# iqn_iqs register map
Vendor: Texas Instruments
Peripheral module from a debugger description file (folder Keystone2).
Registers are 32-bit, read-write, no defined reset value unless marked. A register's access mark holds for its fields unless they carry their own. Offsets are as the file gives them; lines under a group give offsets from that group; [hi:lo] are bit positions; {n}, {i} and the like mark numbered series; 'fields as' and 'values as' point back to an identical list; <NAME> marks a mode.

## IQN_IQS
0x00 IQS_Ingress_PKTDMA_Configuration_Register — (1 of 1, stride 0)
  [0] pb_sel — Sets level where the PKTDMA FIFO pushback occurs on ingress ports that can be pushed back on.
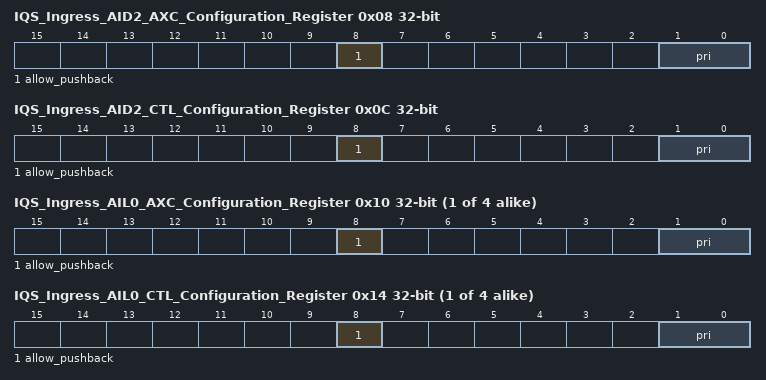
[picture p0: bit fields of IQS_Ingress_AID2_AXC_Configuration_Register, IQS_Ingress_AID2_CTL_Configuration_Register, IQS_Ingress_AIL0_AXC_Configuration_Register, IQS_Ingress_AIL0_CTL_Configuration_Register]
0x08 IQS_Ingress_AID2_AXC_Configuration_Register — (1 of 1, stride 0)
  [8] allow_pushback — When set allows the IQS to push back on the ingress PSI bus of this port due to the PKTDMA FIFO being too full. This allows reserving atleast 1/2 or 1/4 of the PKTDMA FIFO for the non-pushback ports.
  [1:0] pri — Sets ingress port arbitration priority. Typically higher speed standards require higher priorities and control ports can use lower priorities. A 0 is highest priority.
0x0C IQS_Ingress_AID2_CTL_Configuration_Register — (1 of 1, stride 0)
  fields as IQS_Ingress_AID2_AXC_Configuration_Register
{0x10+8i} IQS_Ingress_AIL{i}_AXC_Configuration_Register (i=0..3) — (1 of 1, stride 0)
  fields as IQS_Ingress_AID2_AXC_Configuration_Register
{0x14+8i} IQS_Ingress_AIL{i}_CTL_Configuration_Register (i=0..3) — (1 of 1, stride 0)
  fields as IQS_Ingress_AID2_AXC_Configuration_Register
0x200 IQS_Ingress_DIO2_PSI_Configuration_Register — (1 of 1, stride 0)
  [1:0] pri — Sets ingress DIO2 PSI channel priority. Typically higher speed standards require higher priorities and control ports can use lower priorities. A 0 is highest priority.
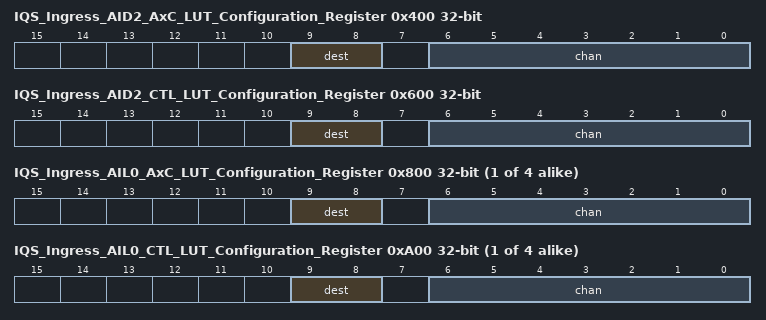
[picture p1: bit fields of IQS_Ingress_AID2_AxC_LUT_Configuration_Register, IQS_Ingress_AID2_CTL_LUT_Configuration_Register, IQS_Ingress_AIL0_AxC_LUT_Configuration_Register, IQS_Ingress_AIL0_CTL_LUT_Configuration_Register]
0x400 IQS_Ingress_AID2_AxC_LUT_Configuration_Register — (1 of 1, stride 0)
  [9:8] dest — Selects destination port.
  [6:0] chan — Channel to use in the destination port.
0x600 IQS_Ingress_AID2_CTL_LUT_Configuration_Register — (1 of 1, stride 0)
  fields as IQS_Ingress_AID2_AxC_LUT_Configuration_Register
{0x800+0x400*i} IQS_Ingress_AIL{i}_AxC_LUT_Configuration_Register (i=0..3) — (1 of 1, stride 0)
  fields as IQS_Ingress_AID2_AxC_LUT_Configuration_Register
{0xA00+0x400*i} IQS_Ingress_AIL{i}_CTL_LUT_Configuration_Register (i=0..3) — (1 of 1, stride 0)
  fields as IQS_Ingress_AID2_AxC_LUT_Configuration_Register
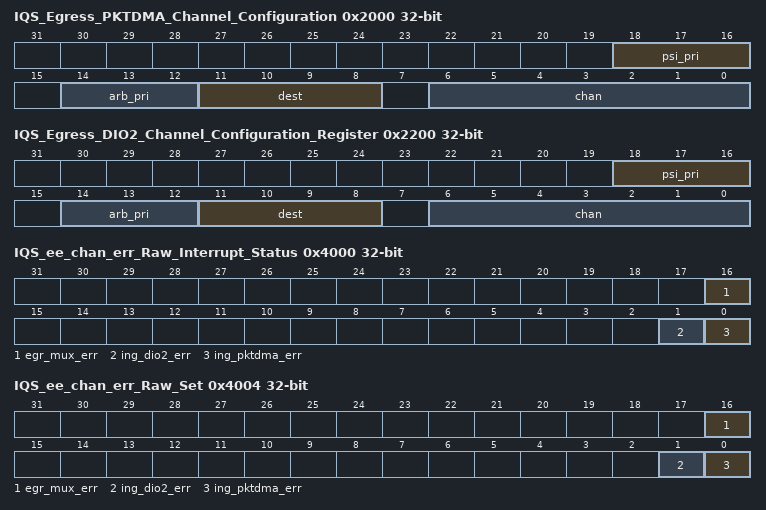
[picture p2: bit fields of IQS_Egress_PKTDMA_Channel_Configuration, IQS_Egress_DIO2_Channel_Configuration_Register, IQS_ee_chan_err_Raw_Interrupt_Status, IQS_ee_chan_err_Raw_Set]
0x2000 IQS_Egress_PKTDMA_Channel_Configuration — (1 of 1, stride 0)
  [18:16] psi_pri — PSI priority from the IQS output FIFOs to the destination module. Typically set the same as the arb_pri setting. A 0 is highest priority.
  [14:12] arb_pri — Arbitration priority of each channel for transfers between the PKTDMA and the output FIFOs. Typically higher speed standards require higher priorities and control ports can use lower priorities. A 0 is highest priority.
  [11:8] dest — Selects destination port.
  [6:0] chan — Channel to use in the destination port.
0x2200 IQS_Egress_DIO2_Channel_Configuration_Register — (1 of 1, stride 0)
  [18:16] psi_pri — PSI priority from the IQS output FIFOs to the destination module. Typically set the same as the arb_pri setting.A 0 is highest priority.
  [14:12] arb_pri — Arbitration priority of each channel for tranfers between the DIO and the output FIFO. Typically higher speed standards require higher priorities and control ports can use lower priorities. A 0 is highest priority.
  [11:8] dest — Selects destination port.
  [6:0] chan — Channel to use in the destination port.
0x4000 IQS_ee_chan_err_Raw_Interrupt_Status ro — (1 of 1, stride 0)
  [16] egr_mux_err — Egress Mux detected a port or channel error. This occurs when the destination port number in the egress PKTDMA or DIO LUT configuration register is higher than the number of output ports available or higher than the maximum number of channels in the
  [1] ing_dio2_err — Ingress DIO2 detected a channel error. This occurs when the destination port number in the ingress port LUT configuration register is higher than the number of channels available in the DIO. This always indicates a programming error.
  [0] ing_pktdma_err — Ingress PKTDMA detected a channel error. This occurs when the destination port number in the ingress port LUT configuration register is higher than the number of channels available in the pktdma. This always indicates a programming error.
0x4004 IQS_ee_chan_err_Raw_Set wo — (1 of 1, stride 0)
  [16] egr_mux_err — Sets the corresponding bit in the raw_status register when written with a 1.
  [1] ing_dio2_err — Sets the corresponding bit in the raw_status register when written with a 1.
  [0] ing_pktdma_err — Sets the corresponding bit in the raw_status register when written with a 1.
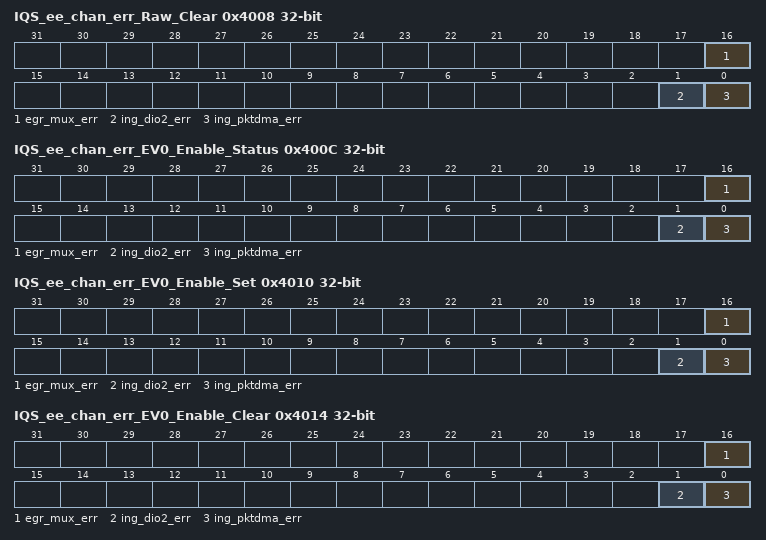
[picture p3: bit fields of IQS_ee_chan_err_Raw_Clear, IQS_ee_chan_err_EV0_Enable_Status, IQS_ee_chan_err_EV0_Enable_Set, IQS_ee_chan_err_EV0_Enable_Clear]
0x4008 IQS_ee_chan_err_Raw_Clear wo — (1 of 1, stride 0)
  [16] egr_mux_err — Clears the corresponding bit in the raw_status register when written with a 1.
  [1] ing_dio2_err — Clears the corresponding bit in the raw_status register when written with a 1.
  [0] ing_pktdma_err — Clears the corresponding bit in the raw_status register when written with a 1.
0x400C IQS_ee_chan_err_EV0_Enable_Status ro — (1 of 1, stride 0)
  [16] egr_mux_err — When high enables the corresponding raw status bit to generate an interrupt.
  [1] ing_dio2_err — When high enables the corresponding raw status bit to generate an interrupt.
  [0] ing_pktdma_err — When high enables the corresponding raw status bit to generate an interrupt.
0x4010 IQS_ee_chan_err_EV0_Enable_Set wo — (1 of 1, stride 0)
  [16] egr_mux_err — Sets the corresponding bit in the enable register when written with a 1.
  [1] ing_dio2_err — Sets the corresponding bit in the enable register when written with a 1.
  [0] ing_pktdma_err — Sets the corresponding bit in the enable register when written with a 1.
0x4014 IQS_ee_chan_err_EV0_Enable_Clear wo — (1 of 1, stride 0)
  [16] egr_mux_err — Clears the corresponding bit in the enable register when written with a 1.
  [1] ing_dio2_err — Clears the corresponding bit in the enable register when written with a 1.
  [0] ing_pktdma_err — Clears the corresponding bit in the enable register when written with a 1.
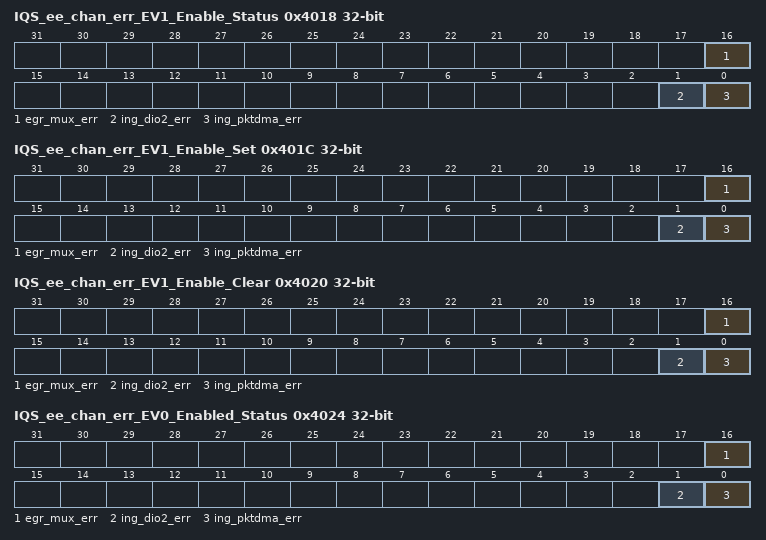
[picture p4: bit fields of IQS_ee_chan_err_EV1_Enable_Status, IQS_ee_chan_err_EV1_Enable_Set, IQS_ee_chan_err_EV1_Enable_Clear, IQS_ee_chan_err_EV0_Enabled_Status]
0x4018 IQS_ee_chan_err_EV1_Enable_Status ro — (1 of 1, stride 0)
  fields as IQS_ee_chan_err_EV0_Enable_Status
0x401C IQS_ee_chan_err_EV1_Enable_Set wo — (1 of 1, stride 0)
  fields as IQS_ee_chan_err_EV0_Enable_Set
0x4020 IQS_ee_chan_err_EV1_Enable_Clear wo — (1 of 1, stride 0)
  fields as IQS_ee_chan_err_EV0_Enable_Clear
0x4024 IQS_ee_chan_err_EV0_Enabled_Status ro — (1 of 1, stride 0)
  [16] egr_mux_err — When high indicates the interrupt is active due to the corresponding bit in the raw status register.
  [1] ing_dio2_err — When high indicates the interrupt is active due to the corresponding bit in the raw status register.
  [0] ing_pktdma_err — When high indicates the interrupt is active due to the corresponding bit in the raw status register.
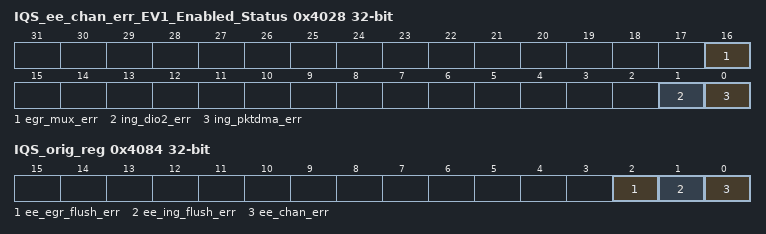
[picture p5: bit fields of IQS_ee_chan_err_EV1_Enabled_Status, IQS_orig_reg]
0x4028 IQS_ee_chan_err_EV1_Enabled_Status ro — (1 of 1, stride 0)
  fields as IQS_ee_chan_err_EV0_Enabled_Status
0x402C IQS_ee_ing_flush_err_Raw_Interrupt_Status ro — (1 of 1, stride 0)
  [15:0] flush — DIO2 Ingress path detected a flush condition. Either the DIO2 detected a flush or there was a write to the DIO2 Ingress FIFO when the FIFO for that channel was full.
0x4030 IQS_ee_ing_flush_err_Raw_Set wo — (1 of 1, stride 0)
  [15:0] flush — Sets the corresponding bit in the raw_status register when written with a 1.
0x4034 IQS_ee_ing_flush_err_Raw_Clear wo — (1 of 1, stride 0)
  [15:0] flush — Clears the corresponding bit in the raw_status register when written with a 1.
0x4038 IQS_ee_ing_flush_err_EV0_Enable_Status ro — (1 of 1, stride 0)
  [15:0] flush — When high enables the corresponding raw status bit to generate an interrupt.
0x403C IQS_ee_ing_flush_err_EV0_Enable_Set wo — (1 of 1, stride 0)
  [15:0] flush — Sets the corresponding bit in the enable register when written with a 1.
0x4040 IQS_ee_ing_flush_err_EV0_Enable_Clear wo — (1 of 1, stride 0)
  [15:0] flush — Clears the corresponding bit in the enable register when written with a 1.
0x4044 IQS_ee_ing_flush_err_EV1_Enable_Status ro — (1 of 1, stride 0)
  fields as IQS_ee_ing_flush_err_EV0_Enable_Status
0x4048 IQS_ee_ing_flush_err_EV1_Enable_Set wo — (1 of 1, stride 0)
  fields as IQS_ee_ing_flush_err_EV0_Enable_Set
0x404C IQS_ee_ing_flush_err_EV1_Enable_Clear wo — (1 of 1, stride 0)
  fields as IQS_ee_ing_flush_err_EV0_Enable_Clear
0x4050 IQS_ee_ing_flush_err_EV0_Enabled_Status ro — (1 of 1, stride 0)
  [15:0] flush — When high indicates the interrupt is active due to the corresponding bit in the raw status register.
0x4054 IQS_ee_ing_flush_err_EV1_Enabled_Status ro — (1 of 1, stride 0)
  fields as IQS_ee_ing_flush_err_EV0_Enabled_Status
0x4058 IQS_ee_egr_flush_err_Raw_Interrupt_Status ro — (1 of 1, stride 0)
  [15:0] flush — DIO2 Egress path detected a flush condition. Either the Destination port generated a flush or there was a write to the DIO2 Egress FIFO when the FIFO for that channel was full.
0x405C IQS_ee_egr_flush_err_Raw_Set wo — (1 of 1, stride 0)
  fields as IQS_ee_ing_flush_err_Raw_Set
0x4060 IQS_ee_egr_flush_err_Raw_Clear wo — (1 of 1, stride 0)
  fields as IQS_ee_ing_flush_err_Raw_Clear
0x4064 IQS_ee_egr_flush_err_EV0_Enable_Status ro — (1 of 1, stride 0)
  fields as IQS_ee_ing_flush_err_EV0_Enable_Status
0x4068 IQS_ee_egr_flush_err_EV0_Enable_Set wo — (1 of 1, stride 0)
  fields as IQS_ee_ing_flush_err_EV0_Enable_Set
0x406C IQS_ee_egr_flush_err_EV0_Enable_Clear wo — (1 of 1, stride 0)
  fields as IQS_ee_ing_flush_err_EV0_Enable_Clear
0x4070 IQS_ee_egr_flush_err_EV1_Enable_Status ro — (1 of 1, stride 0)
  fields as IQS_ee_ing_flush_err_EV0_Enable_Status
0x4074 IQS_ee_egr_flush_err_EV1_Enable_Set wo — (1 of 1, stride 0)
  fields as IQS_ee_ing_flush_err_EV0_Enable_Set
0x4078 IQS_ee_egr_flush_err_EV1_Enable_Clear wo — (1 of 1, stride 0)
  fields as IQS_ee_ing_flush_err_EV0_Enable_Clear
0x407C IQS_ee_egr_flush_err_EV0_Enabled_Status ro — (1 of 1, stride 0)
  fields as IQS_ee_ing_flush_err_EV0_Enabled_Status
0x4080 IQS_ee_egr_flush_err_EV1_Enabled_Status ro — (1 of 1, stride 0)
  fields as IQS_ee_ing_flush_err_EV0_Enabled_Status
0x4084 IQS_orig_reg ro — (1 of 1, stride 0)
  [2] ee_egr_flush_err — If set a bit is set in the ee_egr_flush_err register.
  [1] ee_ing_flush_err — If set a bit is set in the ee_ing_flush_err register.
  [0] ee_chan_err — If set a bit is set in the ee_chan_err register.
